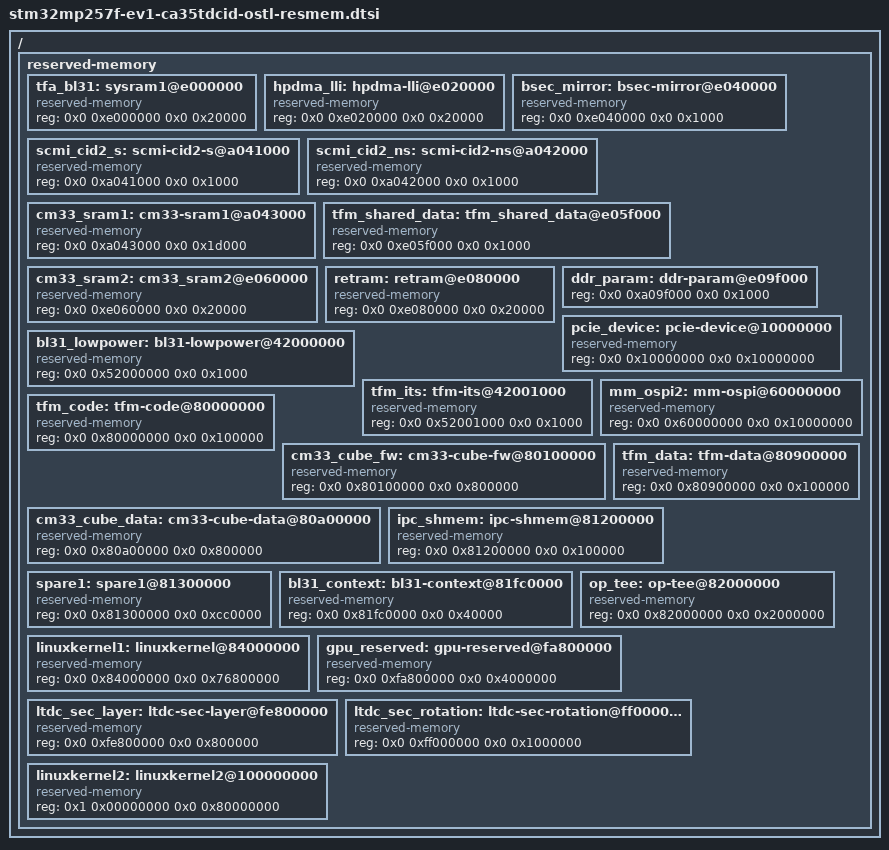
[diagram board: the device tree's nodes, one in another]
// SPDX-License-Identifier: (GPL-2.0-only OR BSD-3-Clause)
/*
 * Copyright (C) STMicroelectronics 2022 - All Rights Reserved
 * Author: Loic Pallardy loic.pallardy@foss.st.com for STMicroelectronics.
 */

/*
 * STM32MP25 reserved memory device tree configuration
 * Project : ostl
 * Generated by XLmx tool version 2.2 - 4/9/2024 2:09:58 PM
 */

/ {
	reserved-memory {
		#address-cells = <2>;
		#size-cells = <2>;
		ranges;

		/* Internal RAM reserved memory declaration */
		tfa_bl31: sysram1@e000000 {
			compatible = "reserved-memory";
			reg = <0x0 0xe000000 0x0 0x20000>;
			#memory-region-cells = <0>;
		};

		hpdma_lli: hpdma-lli@e020000 {
			compatible = "reserved-memory";
			reg = <0x0 0xe020000 0x0 0x20000>;
			#memory-region-cells = <0>;
		};

		bsec_mirror: bsec-mirror@e040000 {
			compatible = "reserved-memory";
			reg = <0x0 0xe040000 0x0 0x1000>;
			#memory-region-cells = <0>;
		};

		scmi_cid2_s: scmi-cid2-s@a041000 {
			compatible = "reserved-memory";
			reg = <0x0 0xa041000 0x0 0x1000>;
			#memory-region-cells = <0>;
		};

		scmi_cid2_ns: scmi-cid2-ns@a042000 {
			compatible = "reserved-memory";
			reg = <0x0 0xa042000 0x0 0x1000>;
			#memory-region-cells = <0>;
		};

		cm33_sram1: cm33-sram1@a043000 {
			compatible = "reserved-memory";
			reg = <0x0 0xa043000 0x0 0x1d000>;
			#memory-region-cells = <0>;
		};
		/*end of areas not used in bl2 */

		tfm_shared_data: tfm_shared_data@e05f000 {
			compatible = "reserved-memory";
			reg = <0x0 0xe05f000 0x0 0x1000>;
			#memory-region-cells = <0>;
		};

		cm33_sram2: cm33_sram2@e060000 {
			compatible = "reserved-memory";
			reg = <0x0 0xe060000 0x0 0x20000>;
			#memory-region-cells = <0>;
		};

		retram: retram@e080000 {
			compatible = "reserved-memory";
			reg = <0x0 0xe080000 0x0 0x20000>;
			#memory-region-cells = <0>;
		};

		ddr_param: ddr-param@e09f000 {
			reg = <0x0 0xa09f000 0x0 0x1000>;
			#memory-region-cells = <0>;
		};

		/* PCIe reserved memory declaration */
		pcie_device: pcie-device@10000000 {
			compatible = "reserved-memory";
			reg = <0x0 0x10000000 0x0 0x10000000>;
			#memory-region-cells = <0>;
		};

		/* Backup RAM reserved memory declaration */
		bl31_lowpower: bl31-lowpower@42000000 {
			compatible = "reserved-memory";
			reg = <0x0 0x52000000 0x0 0x1000>;
			#memory-region-cells = <0>;
		};

		tfm_its: tfm-its@42001000 {
			compatible = "reserved-memory";
			reg = <0x0 0x52001000 0x0 0x1000>;
			#memory-region-cells = <0>;
		};

		/* Octo Memory Manager reserved memory declaration */
		mm_ospi2: mm-ospi@60000000 {
			compatible = "reserved-memory";
			reg = <0x0 0x60000000 0x0 0x10000000>;
			#memory-region-cells = <0>;
		};

		/* DDR reserved memory declaration */
		tfm_code: tfm-code@80000000 {
			compatible = "reserved-memory";
			reg = <0x0 0x80000000 0x0 0x100000>;
			#memory-region-cells = <0>;
		};

		cm33_cube_fw: cm33-cube-fw@80100000 {
			compatible = "reserved-memory";
			reg = <0x0 0x80100000 0x0 0x800000>;
			#memory-region-cells = <0>;
		};

		tfm_data: tfm-data@80900000 {
			compatible = "reserved-memory";
			reg = <0x0 0x80900000 0x0 0x100000>;
			#memory-region-cells = <0>;
		};

		cm33_cube_data: cm33-cube-data@80a00000 {
			compatible = "reserved-memory";
			reg = <0x0 0x80a00000 0x0 0x800000>;
			#memory-region-cells = <0>;
		};

		ipc_shmem: ipc-shmem@81200000 {
			compatible = "reserved-memory";
			reg = <0x0 0x81200000 0x0 0x100000>;
			#memory-region-cells = <0>;
		};

		spare1: spare1@81300000 {
			compatible = "reserved-memory";
			reg = <0x0 0x81300000 0x0 0xcc0000>;
			#memory-region-cells = <0>;
		};

		bl31_context: bl31-context@81fc0000 {
			compatible = "reserved-memory";
			reg = <0x0 0x81fc0000 0x0 0x40000>;
			#memory-region-cells = <0>;
		};

		op_tee: op-tee@82000000 {
			compatible = "reserved-memory";
			reg = <0x0 0x82000000 0x0 0x2000000>;
			#memory-region-cells = <0>;
		};

		linuxkernel1: linuxkernel@84000000 {
			compatible = "reserved-memory";
			reg = <0x0 0x84000000 0x0 0x76800000>;
			#memory-region-cells = <0>;
		};

		gpu_reserved: gpu-reserved@fa800000 {
			compatible = "reserved-memory";
			reg = <0x0 0xfa800000 0x0 0x4000000>;
			#memory-region-cells = <0>;
		};

		ltdc_sec_layer: ltdc-sec-layer@fe800000 {
			compatible = "reserved-memory";
			reg = <0x0 0xfe800000 0x0 0x800000>;
			#memory-region-cells = <0>;
		};

		ltdc_sec_rotation: ltdc-sec-rotation@ff000000 {
			compatible = "reserved-memory";
			reg = <0x0 0xff000000 0x0 0x1000000>;
			#memory-region-cells = <0>;
		};

		linuxkernel2: linuxkernel2@100000000 {
			compatible = "reserved-memory";
			reg = <0x1 0x00000000 0x0 0x80000000>;
			#memory-region-cells = <0>;
		};

	};
};
